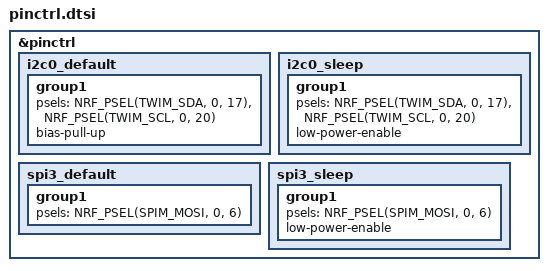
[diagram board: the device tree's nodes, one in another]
/*
* pro_micro == D
* nrf       == gpio
*                    _________________________
*                    |o B+               B- o|
*                    |o RAW             006 o| gpio0 6  D1    LED
*                    |o GND             008 o| gpio0 8  D0    DATA
*                    |o RST             GND o|
*                    |o VCC             GND o|
* ENCA  D21 gpio0 31 |o 031             017 o| gpio0 17 D2    SDA
* ENCB  D20 gpio0 29 |o 029  NRF52840   020 o| gpio0 20 D3    SCL
* COL0  D19 gpio0 2  |o 002             022 o| gpio0 22 D4    
* COL1  D18 gpio1 15 |o 115             024 o| gpio0 24 D5    ROW0
* COL2  D15 gpio1 13 |o 113 o VDD 1 1 1 100 o| gpio1 0  D6    ROW1
* COL3  D14 gpio1 11 |o 111 o DIO 0 0 0 011 o| gpio0 11 D7    ROW2
* COL4  D16 gpio0 10 |o 010 o CLK 7 2 1 104 o| gpio1 4  D8    ROW3
* SW25A D10 gpio0 9  |o 009 o GND o o o 106 o| gpio1 6  D9    ROW4
*                    -------------------------
*                                 | | \ gpio1 1
*                                 | \__ gpio1 2 RST
*                                 \____ gpio1 7 RDY
*/

/*
* |-------|----------|
* | TPS43 | NRF52840 |
* |-------|----------|
* | SDA   | gpio0 17 |
* | SCL   | gpio0 20 |
* | 3V3   | VCC      |
* | GND   | GND      |
* | RST   | gpio1 2  |
* | RDY   | gpio1 7  |
* |-------|----------|
*/

&pinctrl {
    i2c0_default: i2c0_default {
        group1 {
            psels = <NRF_PSEL(TWIM_SDA, 0, 17)>,
                    <NRF_PSEL(TWIM_SCL, 0, 20)>;
            bias-pull-up;
        };
    };

    i2c0_sleep: i2c0_sleep {
        group1 {
            psels = <NRF_PSEL(TWIM_SDA, 0, 17)>,
                    <NRF_PSEL(TWIM_SCL, 0, 20)>;
            low-power-enable;
        };
    };

    spi3_default: spi3_default {
        group1 {
            psels = <NRF_PSEL(SPIM_MOSI, 0, 6)>;
        };
    };

    spi3_sleep: spi3_sleep {
        group1 {
            psels = <NRF_PSEL(SPIM_MOSI, 0, 6)>;
            low-power-enable;
        };
    };
};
